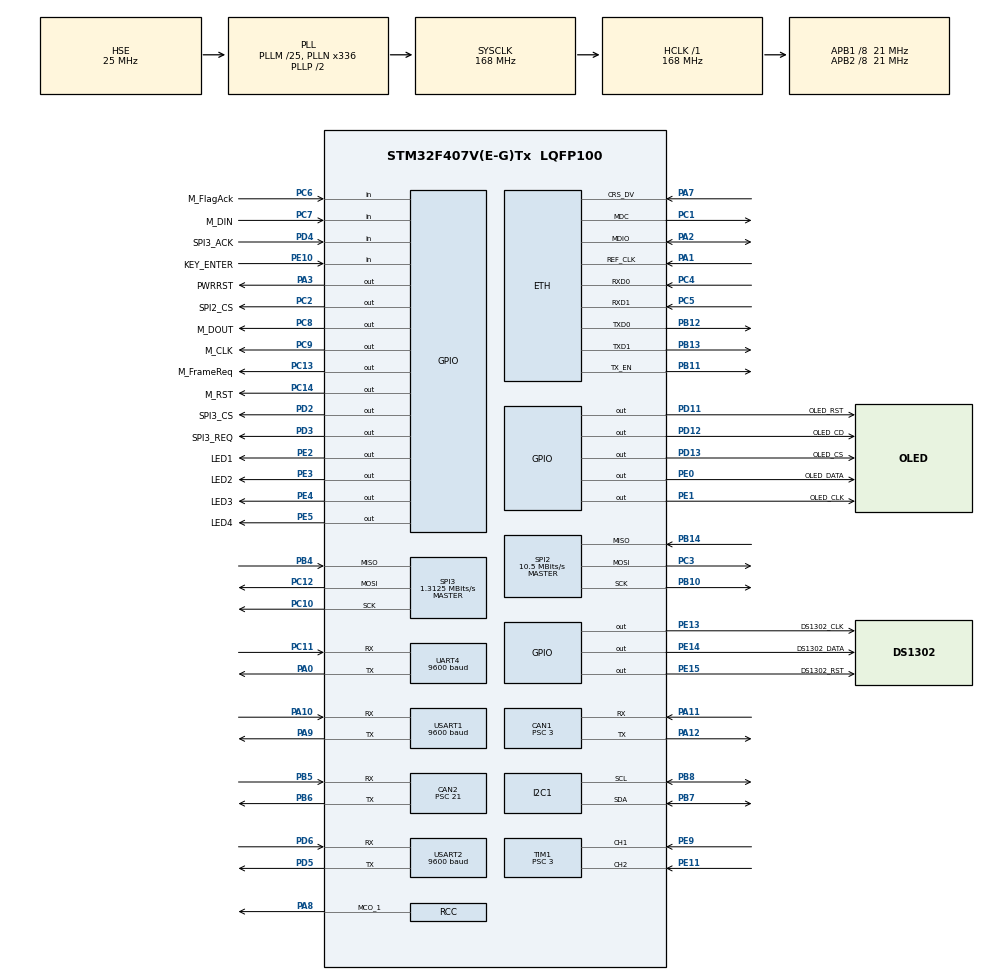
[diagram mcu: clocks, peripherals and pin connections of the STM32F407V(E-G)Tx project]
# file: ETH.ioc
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CAN1.BS1=CAN_BS1_4TQ
CAN1.BS2=CAN_BS2_2TQ
CAN1.CalculateBaudRate=1000000
CAN1.CalculateTimeQuantum=142.85714285714286
CAN1.Mode=CAN_MODE_NORMAL
CAN1.Prescaler=3
CAN2.BS1=CAN_BS1_5TQ
CAN2.BS2=CAN_BS2_2TQ
CAN2.CalculateBaudRate=125000
CAN2.CalculateTimeBit=8000
CAN2.CalculateTimeQuantum=1000.0
CAN2.Mode=CAN_MODE_NORMAL
CAN2.Prescaler=21
Dma.Request0=USART1_RX
Dma.Request1=USART1_TX
Dma.Request2=USART2_RX
Dma.Request3=USART2_TX
Dma.Request4=UART4_RX
Dma.Request5=UART4_TX
Dma.UART4_RX.4.Direction=DMA_PERIPH_TO_MEMORY
Dma.UART4_RX.4.FIFOMode=DMA_FIFOMODE_DISABLE
Dma.UART4_RX.4.Instance=DMA1_Stream2
Dma.UART4_RX.4.MemDataAlignment=DMA_MDATAALIGN_BYTE
Dma.UART4_RX.4.MemInc=DMA_MINC_ENABLE
Dma.UART4_RX.4.Mode=DMA_NORMAL
Dma.UART4_RX.4.PeriphDataAlignment=DMA_PDATAALIGN_BYTE
Dma.UART4_RX.4.PeriphInc=DMA_PINC_DISABLE
Dma.UART4_RX.4.Priority=DMA_PRIORITY_LOW
Dma.UART4_TX.5.Direction=DMA_MEMORY_TO_PERIPH
Dma.UART4_TX.5.FIFOMode=DMA_FIFOMODE_DISABLE
Dma.UART4_TX.5.Instance=DMA1_Stream4
Dma.UART4_TX.5.MemDataAlignment=DMA_MDATAALIGN_BYTE
Dma.UART4_TX.5.MemInc=DMA_MINC_ENABLE
Dma.UART4_TX.5.Mode=DMA_NORMAL
Dma.UART4_TX.5.PeriphDataAlignment=DMA_PDATAALIGN_BYTE
Dma.UART4_TX.5.PeriphInc=DMA_PINC_DISABLE
Dma.UART4_TX.5.Priority=DMA_PRIORITY_LOW
Dma.USART1_RX.0.Direction=DMA_PERIPH_TO_MEMORY
Dma.USART1_RX.0.FIFOMode=DMA_FIFOMODE_DISABLE
Dma.USART1_RX.0.Instance=DMA2_Stream2
Dma.USART1_RX.0.MemDataAlignment=DMA_MDATAALIGN_BYTE
Dma.USART1_RX.0.MemInc=DMA_MINC_ENABLE
Dma.USART1_RX.0.Mode=DMA_NORMAL
Dma.USART1_RX.0.PeriphDataAlignment=DMA_PDATAALIGN_BYTE
Dma.USART1_RX.0.PeriphInc=DMA_PINC_DISABLE
Dma.USART1_RX.0.Priority=DMA_PRIORITY_LOW
Dma.USART1_TX.1.Direction=DMA_MEMORY_TO_PERIPH
Dma.USART1_TX.1.FIFOMode=DMA_FIFOMODE_DISABLE
Dma.USART1_TX.1.Instance=DMA2_Stream7
Dma.USART1_TX.1.MemDataAlignment=DMA_MDATAALIGN_BYTE
Dma.USART1_TX.1.MemInc=DMA_MINC_ENABLE
Dma.USART1_TX.1.Mode=DMA_NORMAL
Dma.USART1_TX.1.PeriphDataAlignment=DMA_PDATAALIGN_BYTE
Dma.USART1_TX.1.PeriphInc=DMA_PINC_DISABLE
Dma.USART1_TX.1.Priority=DMA_PRIORITY_LOW
Dma.USART2_RX.2.Direction=DMA_PERIPH_TO_MEMORY
Dma.USART2_RX.2.FIFOMode=DMA_FIFOMODE_DISABLE
Dma.USART2_RX.2.Instance=DMA1_Stream5
Dma.USART2_RX.2.MemDataAlignment=DMA_MDATAALIGN_BYTE
Dma.USART2_RX.2.MemInc=DMA_MINC_ENABLE
Dma.USART2_RX.2.Mode=DMA_NORMAL
Dma.USART2_RX.2.PeriphDataAlignment=DMA_PDATAALIGN_BYTE
Dma.USART2_RX.2.PeriphInc=DMA_PINC_DISABLE
Dma.USART2_RX.2.Priority=DMA_PRIORITY_LOW
Dma.USART2_TX.3.Direction=DMA_MEMORY_TO_PERIPH
Dma.USART2_TX.3.FIFOMode=DMA_FIFOMODE_DISABLE
Dma.USART2_TX.3.Instance=DMA1_Stream6
Dma.USART2_TX.3.MemDataAlignment=DMA_MDATAALIGN_BYTE
Dma.USART2_TX.3.MemInc=DMA_MINC_ENABLE
Dma.USART2_TX.3.Mode=DMA_NORMAL
Dma.USART2_TX.3.PeriphDataAlignment=DMA_PDATAALIGN_BYTE
Dma.USART2_TX.3.PeriphInc=DMA_PINC_DISABLE
Dma.USART2_TX.3.Priority=DMA_PRIORITY_LOW
ETH.MediaInterface=HAL_ETH_RMII_MODE
ETH.PHY_DUPLEX_STATUS=0x0010
ETH.PHY_Name_RMII=userPHY
ETH.PHY_SPEED_STATUS=0x0004
ETH.PHY_SR=31
ETH.PHY_User_Name=LAN8720
I2C1.OwnAddress=20
Mcu.Family=STM32F4
Mcu.Name=STM32F407V(E-G)Tx
Mcu.Package=LQFP100
NVIC.CAN1_RX0_IRQn=true\:0\:0\:false\:false\:true\:true\:true\:true
NVIC.CAN1_TX_IRQn=true\:0\:0\:false\:false\:true\:true\:true\:true
NVIC.CAN2_RX0_IRQn=true\:0\:0\:false\:false\:true\:true\:true\:true
NVIC.DMA1_Stream2_IRQn=true\:0\:0\:false\:false\:true\:false\:true\:true
NVIC.DMA1_Stream4_IRQn=true\:0\:0\:false\:false\:true\:false\:true\:true
NVIC.DMA1_Stream5_IRQn=true\:0\:0\:false\:false\:true\:false\:true\:true
NVIC.DMA1_Stream6_IRQn=true\:0\:0\:false\:false\:true\:false\:true\:true
NVIC.DMA2_Stream2_IRQn=true\:0\:0\:false\:false\:true\:false\:true\:true
NVIC.DMA2_Stream7_IRQn=true\:0\:0\:false\:false\:true\:false\:true\:true
NVIC.ETH_IRQn=true\:0\:0\:false\:false\:true\:true\:true\:true
NVIC.PriorityGroup=NVIC_PRIORITYGROUP_4
NVIC.TIM6_DAC_IRQn=true\:15\:0\:false\:false\:true\:false\:true\:true
NVIC.TimeBase=TIM6_DAC_IRQn
NVIC.TimeBaseIP=TIM6
NVIC.UART4_IRQn=true\:0\:0\:false\:false\:true\:true\:true\:true
NVIC.USART1_IRQn=true\:0\:0\:false\:false\:true\:true\:true\:true
NVIC.USART2_IRQn=true\:0\:0\:false\:false\:true\:true\:true\:true
PA0-WKUP.Mode=Asynchronous
PA0-WKUP.Signal=UART4_TX
PA1.Mode=RMII
PA1.Signal=ETH_REF_CLK
PA10.Mode=Asynchronous
PA10.Signal=USART1_RX
PA11.Mode=CAN_Activate
PA11.Signal=CAN1_RX
PA12.Mode=CAN_Activate
PA12.Signal=CAN1_TX
PA13.Mode=Serial_Wire
PA13.Signal=SYS_JTMS-SWDIO
PA14.Mode=Serial_Wire
PA14.Signal=SYS_JTCK-SWCLK
PA2.Mode=RMII
PA2.Signal=ETH_MDIO
PA3.GPIO_Label=PWRRST
PA3.Signal=GPIO_Output
PA7.Mode=RMII
PA7.Signal=ETH_CRS_DV
PA8.Mode=Clock-out-1
PA8.Signal=RCC_MCO_1
PA9.Mode=Asynchronous
PA9.Signal=USART1_TX
PB10.Mode=Full_Duplex_Master
PB10.Signal=SPI2_SCK
PB11.Mode=RMII
PB11.Signal=ETH_TX_EN
PB12.Mode=RMII
PB12.Signal=ETH_TXD0
PB13.Mode=RMII
PB13.Signal=ETH_TXD1
PB14.Mode=Full_Duplex_Master
PB14.Signal=SPI2_MISO
PB4.Mode=Full_Duplex_Master
PB4.Signal=SPI3_MISO
PB5.Mode=CAN_Activate
PB5.Signal=CAN2_RX
PB6.Mode=CAN_Activate
PB6.Signal=CAN2_TX
PB7.GPIO_Pu=GPIO_PULLUP
PB7.Mode=I2C
PB7.Signal=I2C1_SDA
PB8.GPIO_Pu=GPIO_PULLUP
PB8.Mode=I2C
PB8.Signal=I2C1_SCL
PC1.Mode=RMII
PC1.Signal=ETH_MDC
PC10.Mode=Full_Duplex_Master
PC10.Signal=SPI3_SCK
PC11.Mode=Asynchronous
PC11.Signal=UART4_RX
PC12.Mode=Full_Duplex_Master
PC12.Signal=SPI3_MOSI
PC13-ANTI_TAMP.GPIO_Label=M_FrameReq
PC13-ANTI_TAMP.Signal=GPIO_Output
PC14-OSC32_IN.GPIO_Label=M_RST
PC14-OSC32_IN.Signal=GPIO_Output
PC2.GPIO_Label=SPI2_CS
PC2.Signal=GPIO_Output
PC3.Mode=Full_Duplex_Master
PC3.Signal=SPI2_MOSI
PC4.Mode=RMII
PC4.Signal=ETH_RXD0
PC5.Mode=RMII
PC5.Signal=ETH_RXD1
PC6.GPIO_Label=M_FlagAck
PC6.Signal=GPIO_Input
PC7.GPIO_Label=M_DIN
PC7.Signal=GPIO_Input
PC8.GPIO_Label=M_DOUT
PC8.Signal=GPIO_Output
PC9.GPIO_Label=M_CLK
PC9.Signal=GPIO_Output
PD11.GPIO_Label=OLED_RST
PD11.Signal=GPIO_Output
PD12.GPIO_Label=OLED_CD
PD12.Signal=GPIO_Output
PD13.GPIO_Label=OLED_CS
PD13.Signal=GPIO_Output
PD2.GPIO_Label=SPI3_CS
PD2.Signal=GPIO_Output
PD3.GPIO_Label=SPI3_REQ
PD3.Signal=GPIO_Output
PD4.GPIO_Label=SPI3_ACK
PD4.Signal=GPIO_Input
PD5.Mode=Asynchronous
PD5.Signal=USART2_TX
PD6.Mode=Asynchronous
PD6.Signal=USART2_RX
PE0.GPIO_Label=OLED_DATA
PE0.Signal=GPIO_Output
PE1.GPIO_Label=OLED_CLK
PE1.Signal=GPIO_Output
PE10.GPIO_Label=KEY_ENTER
PE10.Signal=GPIO_Input
PE11.Signal=S_TIM1_CH2
PE13.GPIO_Label=DS1302_CLK
PE13.Signal=GPIO_Output
PE14.GPIO_Label=DS1302_DATA
PE14.Signal=GPIO_Output
PE15.GPIO_Label=DS1302_RST
PE15.Signal=GPIO_Output
PE2.GPIO_Label=LED1
PE2.Signal=GPIO_Output
PE3.GPIO_Label=LED2
PE3.Signal=GPIO_Output
PE4.GPIO_Label=LED3
PE4.Signal=GPIO_Output
PE5.GPIO_Label=LED4
PE5.Signal=GPIO_Output
PE9.Signal=S_TIM1_CH1
PH0-OSC_IN.Mode=HSE-External-Oscillator
PH0-OSC_IN.Signal=RCC_OSC_IN
PH1-OSC_OUT.Mode=HSE-External-Oscillator
PH1-OSC_OUT.Signal=RCC_OSC_OUT
ProjectManager.HeapSize=0x200
ProjectManager.StackSize=0x400
ProjectManager.TargetToolchain=Makefile
RCC.48MHZClocksFreq_Value=84000000
RCC.AHBFreq_Value=168000000
RCC.APB1CLKDivider=RCC_HCLK_DIV8
RCC.APB1Freq_Value=21000000
RCC.APB1TimFreq_Value=42000000
RCC.APB2CLKDivider=RCC_HCLK_DIV8
RCC.APB2Freq_Value=21000000
RCC.APB2TimFreq_Value=42000000
RCC.CortexFreq_Value=168000000
RCC.HCLKFreq_Value=168000000
RCC.HSE_VALUE=25000000
RCC.HSI_VALUE=16000000
RCC.LSE_VALUE=32768
RCC.PLLM=25
RCC.PLLN=336
RCC.PLLSourceVirtual=RCC_PLLSOURCE_HSE
RCC.RCC_RTC_Clock_Source=RCC_RTCCLKSOURCE_HSE_DIV25
RCC.RCC_RTC_Clock_SourceVirtual=RCC_RTCCLKSOURCE_LSE
RCC.RCC_RTC_Clock_Source_FROM_HSE=RCC_RTCCLKSOURCE_HSE_DIV25
RCC.SYSCLKFreq_VALUE=168000000
RCC.SYSCLKSource=RCC_SYSCLKSOURCE_PLLCLK
RCC.VCOOutputFreq_Value=336000000
SH.S_TIM1_CH1.0=TIM1_CH1,Encoder_Interface
SH.S_TIM1_CH2.0=TIM1_CH2,Encoder_Interface
SPI2.CalculateBaudRate=10.5 MBits/s
SPI2.Direction=SPI_DIRECTION_2LINES
SPI2.Mode=SPI_MODE_MASTER
SPI2.VirtualType=VM_MASTER
SPI3.BaudRatePrescaler=SPI_BAUDRATEPRESCALER_16
SPI3.CLKPhase=SPI_PHASE_1EDGE
SPI3.CLKPolarity=SPI_POLARITY_LOW
SPI3.CalculateBaudRate=1.3125 MBits/s
SPI3.Direction=SPI_DIRECTION_2LINES
SPI3.FirstBit=SPI_FIRSTBIT_MSB
SPI3.Mode=SPI_MODE_MASTER
SPI3.VirtualType=VM_MASTER
TIM1.Channel-Input_Capture2_from_TI2=TIM_CHANNEL_2
TIM1.EncoderMode=TIM_ENCODERMODE_TI12
TIM1.IC1Filter=15
TIM1.IC2Filter=15
TIM1.Period=0xffff
TIM1.Prescaler=3
UART4.BaudRate=9600
UART4.VirtualMode=Asynchronous
USART1.BaudRate=9600
USART1.VirtualMode=VM_ASYNC
USART2.BaudRate=9600
USART2.VirtualMode=VM_ASYNC
VP_SYS_VS_tim6.Mode=TIM6
board=custom

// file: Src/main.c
/* USER CODE BEGIN Header */
/**
  ******************************************************************************
  * @file           : main.c
  * @brief          : Main program body
  ******************************************************************************
  * @attention
  *
  * Copyright (c) 2023 STMicroelectronics.
  * All rights reserved.
  *
  * This software is licensed under terms that can be found in the LICENSE file
  * in the root directory of this software component.
  * If no LICENSE file comes with this software, it is provided AS-IS.
  *
  ******************************************************************************
  */
/* USER CODE END Header */
#include "main.h"
#include "string.h"

/* USER CODE BEGIN Includes */
#include "mongoose.h"
/* USER CODE END Includes */

ETH_TxPacketConfig TxConfig;
ETH_DMADescTypeDef  DMARxDscrTab[ETH_RX_DESC_CNT]; /* Ethernet Rx DMA Descriptors */
ETH_DMADescTypeDef  DMATxDscrTab[ETH_TX_DESC_CNT]; /* Ethernet Tx DMA Descriptors */

CAN_HandleTypeDef hcan1;
CAN_HandleTypeDef hcan2;

ETH_HandleTypeDef heth;

I2C_HandleTypeDef hi2c1;

SPI_HandleTypeDef hspi2;
SPI_HandleTypeDef hspi3;

TIM_HandleTypeDef htim1;

UART_HandleTypeDef huart4;
UART_HandleTypeDef huart1;
UART_HandleTypeDef huart2;
DMA_HandleTypeDef hdma_uart4_rx;
DMA_HandleTypeDef hdma_uart4_tx;
DMA_HandleTypeDef hdma_usart1_rx;
DMA_HandleTypeDef hdma_usart1_tx;
DMA_HandleTypeDef hdma_usart2_rx;
DMA_HandleTypeDef hdma_usart2_tx;

void SystemClock_Config(void);
static void MX_GPIO_Init(void);
static void MX_DMA_Init(void);
static void MX_USART1_UART_Init(void);
static void MX_SPI3_Init(void);
static void MX_USART2_UART_Init(void);
static void MX_CAN1_Init(void);
static void MX_I2C1_Init(void);
static void MX_UART4_Init(void);
static void MX_SPI2_Init(void);
static void MX_CAN2_Init(void);
static void MX_TIM1_Init(void);
static void MX_ETH_Init(void);

/* USER CODE BEGIN 0 */
uint64_t mg_millis(void) {
  return HAL_GetTick();
}

/* USER CODE END 0 */

int main(void)
{

  /* MCU Configuration--------------------------------------------------------*/

  /* Reset of all peripherals, Initializes the Flash interface and the Systick. */
  HAL_Init();

  /* Configure the system clock */
  SystemClock_Config();

  /* Initialize all configured peripherals */
  MX_GPIO_Init();
  MX_DMA_Init();
  MX_USART1_UART_Init();
  MX_SPI3_Init();
  MX_USART2_UART_Init();
  MX_CAN1_Init();
  MX_I2C1_Init();
  MX_UART4_Init();
  MX_SPI2_Init();
  MX_CAN2_Init();
  MX_TIM1_Init();
  MX_ETH_Init();
  /* USER CODE BEGIN 2 */
  struct mg_mgr mgr;
mg_mgr_init(&mgr);

struct mg_tcpip_if mif = {
    .mac = {2, 0, 1, 2, 3, 4},
    .driver = &mg_tcpip_driver_stm32,
};
mg_tcpip_init(&mgr, &mif);

extern void device_dashboard_fn(struct mg_connection *c, int ev, void *ev_data,
                                void *fn_data);
mg_http_listen(&mgr, "http://0.0.0.0", device_dashboard_fn, NULL);
for (;;) mg_mgr_poll(&mgr, 100);
  /* USER CODE END 2 */

  /* Infinite loop */
  while (1)
  {

  }
}

void SystemClock_Config(void)
{
  RCC_OscInitTypeDef RCC_OscInitStruct = {0};
  RCC_ClkInitTypeDef RCC_ClkInitStruct = {0};

  /** Configure the main internal regulator output voltage
  */
  __HAL_RCC_PWR_CLK_ENABLE();
  __HAL_PWR_VOLTAGESCALING_CONFIG(PWR_REGULATOR_VOLTAGE_SCALE1);

  /** Initializes the RCC Oscillators according to the specified parameters
  * in the RCC_OscInitTypeDef structure.
  */
  RCC_OscInitStruct.OscillatorType = RCC_OSCILLATORTYPE_HSI|RCC_OSCILLATORTYPE_HSE;
  RCC_OscInitStruct.HSEState = RCC_HSE_ON;
  RCC_OscInitStruct.HSIState = RCC_HSI_ON;
  RCC_OscInitStruct.HSICalibrationValue = RCC_HSICALIBRATION_DEFAULT;
  RCC_OscInitStruct.PLL.PLLState = RCC_PLL_ON;
  RCC_OscInitStruct.PLL.PLLSource = RCC_PLLSOURCE_HSE;
  RCC_OscInitStruct.PLL.PLLM = 25;
  RCC_OscInitStruct.PLL.PLLN = 336;
  RCC_OscInitStruct.PLL.PLLP = RCC_PLLP_DIV2;
  RCC_OscInitStruct.PLL.PLLQ = 4;
  if (HAL_RCC_OscConfig(&RCC_OscInitStruct) != HAL_OK)
  {
    Error_Handler();
  }

  /** Initializes the CPU, AHB and APB buses clocks
  */
  RCC_ClkInitStruct.ClockType = RCC_CLOCKTYPE_HCLK|RCC_CLOCKTYPE_SYSCLK
                              |RCC_CLOCKTYPE_PCLK1|RCC_CLOCKTYPE_PCLK2;
  RCC_ClkInitStruct.SYSCLKSource = RCC_SYSCLKSOURCE_PLLCLK;
  RCC_ClkInitStruct.AHBCLKDivider = RCC_SYSCLK_DIV1;
  RCC_ClkInitStruct.APB1CLKDivider = RCC_HCLK_DIV8;
  RCC_ClkInitStruct.APB2CLKDivider = RCC_HCLK_DIV8;

  if (HAL_RCC_ClockConfig(&RCC_ClkInitStruct, FLASH_LATENCY_5) != HAL_OK)
  {
    Error_Handler();
  }
  HAL_RCC_MCOConfig(RCC_MCO1, RCC_MCO1SOURCE_HSI, RCC_MCODIV_1);
}

static void MX_CAN1_Init(void)
{

  hcan1.Instance = CAN1;
  hcan1.Init.Prescaler = 3;
  hcan1.Init.Mode = CAN_MODE_NORMAL;
  hcan1.Init.SyncJumpWidth = CAN_SJW_1TQ;
  hcan1.Init.TimeSeg1 = CAN_BS1_4TQ;
  hcan1.Init.TimeSeg2 = CAN_BS2_2TQ;
  hcan1.Init.TimeTriggeredMode = DISABLE;
  hcan1.Init.AutoBusOff = DISABLE;
  hcan1.Init.AutoWakeUp = DISABLE;
  hcan1.Init.AutoRetransmission = DISABLE;
  hcan1.Init.ReceiveFifoLocked = DISABLE;
  hcan1.Init.TransmitFifoPriority = DISABLE;
  if (HAL_CAN_Init(&hcan1) != HAL_OK)
  {
    Error_Handler();
  }

}

static void MX_CAN2_Init(void)
{

  hcan2.Instance = CAN2;
  hcan2.Init.Prescaler = 21;
  hcan2.Init.Mode = CAN_MODE_NORMAL;
  hcan2.Init.SyncJumpWidth = CAN_SJW_1TQ;
  hcan2.Init.TimeSeg1 = CAN_BS1_5TQ;
  hcan2.Init.TimeSeg2 = CAN_BS2_2TQ;
  hcan2.Init.TimeTriggeredMode = DISABLE;
  hcan2.Init.AutoBusOff = DISABLE;
  hcan2.Init.AutoWakeUp = DISABLE;
  hcan2.Init.AutoRetransmission = DISABLE;
  hcan2.Init.ReceiveFifoLocked = DISABLE;
  hcan2.Init.TransmitFifoPriority = DISABLE;
  if (HAL_CAN_Init(&hcan2) != HAL_OK)
  {
    Error_Handler();
  }

}

static void MX_ETH_Init(void)
{

   static uint8_t MACAddr[6];

  heth.Instance = ETH;
  MACAddr[0] = 0x00;
  MACAddr[1] = 0x80;
  MACAddr[2] = 0xE1;
  MACAddr[3] = 0x00;
  MACAddr[4] = 0x00;
  MACAddr[5] = 0x00;
  heth.Init.MACAddr = &MACAddr[0];
  heth.Init.MediaInterface = HAL_ETH_RMII_MODE;
  heth.Init.TxDesc = DMATxDscrTab;
  heth.Init.RxDesc = DMARxDscrTab;
  heth.Init.RxBuffLen = 1524;

  if (HAL_ETH_Init(&heth) != HAL_OK)
  {
    Error_Handler();
  }

  memset(&TxConfig, 0 , sizeof(ETH_TxPacketConfig));
  TxConfig.Attributes = ETH_TX_PACKETS_FEATURES_CSUM | ETH_TX_PACKETS_FEATURES_CRCPAD;
  TxConfig.ChecksumCtrl = ETH_CHECKSUM_IPHDR_PAYLOAD_INSERT_PHDR_CALC;
  TxConfig.CRCPadCtrl = ETH_CRC_PAD_INSERT;

}

static void MX_I2C1_Init(void)
{

  hi2c1.Instance = I2C1;
  hi2c1.Init.ClockSpeed = 100000;
  hi2c1.Init.DutyCycle = I2C_DUTYCYCLE_2;
  hi2c1.Init.OwnAddress1 = 40;
  hi2c1.Init.AddressingMode = I2C_ADDRESSINGMODE_7BIT;
  hi2c1.Init.DualAddressMode = I2C_DUALADDRESS_DISABLE;
  hi2c1.Init.OwnAddress2 = 0;
  hi2c1.Init.GeneralCallMode = I2C_GENERALCALL_DISABLE;
  hi2c1.Init.NoStretchMode = I2C_NOSTRETCH_DISABLE;
  if (HAL_I2C_Init(&hi2c1) != HAL_OK)
  {
    Error_Handler();
  }

}

static void MX_SPI2_Init(void)
{

  /* SPI2 parameter configuration*/
  hspi2.Instance = SPI2;
  hspi2.Init.Mode = SPI_MODE_MASTER;
  hspi2.Init.Direction = SPI_DIRECTION_2LINES;
  hspi2.Init.DataSize = SPI_DATASIZE_8BIT;
  hspi2.Init.CLKPolarity = SPI_POLARITY_LOW;
  hspi2.Init.CLKPhase = SPI_PHASE_1EDGE;
  hspi2.Init.NSS = SPI_NSS_SOFT;
  hspi2.Init.BaudRatePrescaler = SPI_BAUDRATEPRESCALER_2;
  hspi2.Init.FirstBit = SPI_FIRSTBIT_MSB;
  hspi2.Init.TIMode = SPI_TIMODE_DISABLE;
  hspi2.Init.CRCCalculation = SPI_CRCCALCULATION_DISABLE;
  hspi2.Init.CRCPolynomial = 10;
  if (HAL_SPI_Init(&hspi2) != HAL_OK)
  {
    Error_Handler();
  }

}

static void MX_SPI3_Init(void)
{

  /* SPI3 parameter configuration*/
  hspi3.Instance = SPI3;
  hspi3.Init.Mode = SPI_MODE_MASTER;
  hspi3.Init.Direction = SPI_DIRECTION_2LINES;
  hspi3.Init.DataSize = SPI_DATASIZE_8BIT;
  hspi3.Init.CLKPolarity = SPI_POLARITY_LOW;
  hspi3.Init.CLKPhase = SPI_PHASE_1EDGE;
  hspi3.Init.NSS = SPI_NSS_SOFT;
  hspi3.Init.BaudRatePrescaler = SPI_BAUDRATEPRESCALER_16;
  hspi3.Init.FirstBit = SPI_FIRSTBIT_MSB;
  hspi3.Init.TIMode = SPI_TIMODE_DISABLE;
  hspi3.Init.CRCCalculation = SPI_CRCCALCULATION_DISABLE;
  hspi3.Init.CRCPolynomial = 10;
  if (HAL_SPI_Init(&hspi3) != HAL_OK)
  {
    Error_Handler();
  }

}

static void MX_TIM1_Init(void)
{

  TIM_Encoder_InitTypeDef sConfig = {0};
  TIM_MasterConfigTypeDef sMasterConfig = {0};

  htim1.Instance = TIM1;
  htim1.Init.Prescaler = 3;
  htim1.Init.CounterMode = TIM_COUNTERMODE_UP;
  htim1.Init.Period = 0xffff;
  htim1.Init.ClockDivision = TIM_CLOCKDIVISION_DIV1;
  htim1.Init.RepetitionCounter = 0;
  htim1.Init.AutoReloadPreload = TIM_AUTORELOAD_PRELOAD_DISABLE;
  sConfig.EncoderMode = TIM_ENCODERMODE_TI12;
  sConfig.IC1Polarity = TIM_ICPOLARITY_RISING;
  sConfig.IC1Selection = TIM_ICSELECTION_DIRECTTI;
  sConfig.IC1Prescaler = TIM_ICPSC_DIV1;
  sConfig.IC1Filter = 15;
  sConfig.IC2Polarity = TIM_ICPOLARITY_RISING;
  sConfig.IC2Selection = TIM_ICSELECTION_DIRECTTI;
  sConfig.IC2Prescaler = TIM_ICPSC_DIV1;
  sConfig.IC2Filter = 15;
  if (HAL_TIM_Encoder_Init(&htim1, &sConfig) != HAL_OK)
  {
    Error_Handler();
  }
  sMasterConfig.MasterOutputTrigger = TIM_TRGO_RESET;
  sMasterConfig.MasterSlaveMode = TIM_MASTERSLAVEMODE_DISABLE;
  if (HAL_TIMEx_MasterConfigSynchronization(&htim1, &sMasterConfig) != HAL_OK)
  {
    Error_Handler();
  }

}

static void MX_UART4_Init(void)
{

  huart4.Instance = UART4;
  huart4.Init.BaudRate = 9600;
  huart4.Init.WordLength = UART_WORDLENGTH_8B;
  huart4.Init.StopBits = UART_STOPBITS_1;
  huart4.Init.Parity = UART_PARITY_NONE;
  huart4.Init.Mode = UART_MODE_TX_RX;
  huart4.Init.HwFlowCtl = UART_HWCONTROL_NONE;
  huart4.Init.OverSampling = UART_OVERSAMPLING_16;
  if (HAL_UART_Init(&huart4) != HAL_OK)
  {
    Error_Handler();
  }

}

static void MX_USART1_UART_Init(void)
{

  huart1.Instance = USART1;
  huart1.Init.BaudRate = 9600;
  huart1.Init.WordLength = UART_WORDLENGTH_8B;
  huart1.Init.StopBits = UART_STOPBITS_1;
  huart1.Init.Parity = UART_PARITY_NONE;
  huart1.Init.Mode = UART_MODE_TX_RX;
  huart1.Init.HwFlowCtl = UART_HWCONTROL_NONE;
  huart1.Init.OverSampling = UART_OVERSAMPLING_16;
  if (HAL_UART_Init(&huart1) != HAL_OK)
  {
    Error_Handler();
  }

}

static void MX_USART2_UART_Init(void)
{

  huart2.Instance = USART2;
  huart2.Init.BaudRate = 9600;
  huart2.Init.WordLength = UART_WORDLENGTH_8B;
  huart2.Init.StopBits = UART_STOPBITS_1;
  huart2.Init.Parity = UART_PARITY_NONE;
  huart2.Init.Mode = UART_MODE_TX_RX;
  huart2.Init.HwFlowCtl = UART_HWCONTROL_NONE;
  huart2.Init.OverSampling = UART_OVERSAMPLING_16;
  if (HAL_UART_Init(&huart2) != HAL_OK)
  {
    Error_Handler();
  }

}

static void MX_DMA_Init(void)
{

  /* DMA controller clock enable */
  __HAL_RCC_DMA2_CLK_ENABLE();
  __HAL_RCC_DMA1_CLK_ENABLE();

  /* DMA interrupt init */
  /* DMA1_Stream2_IRQn interrupt configuration */
  HAL_NVIC_SetPriority(DMA1_Stream2_IRQn, 0, 0);
  HAL_NVIC_EnableIRQ(DMA1_Stream2_IRQn);
  /* DMA1_Stream4_IRQn interrupt configuration */
  HAL_NVIC_SetPriority(DMA1_Stream4_IRQn, 0, 0);
  HAL_NVIC_EnableIRQ(DMA1_Stream4_IRQn);
  /* DMA1_Stream5_IRQn interrupt configuration */
  HAL_NVIC_SetPriority(DMA1_Stream5_IRQn, 0, 0);
  HAL_NVIC_EnableIRQ(DMA1_Stream5_IRQn);
  /* DMA1_Stream6_IRQn interrupt configuration */
  HAL_NVIC_SetPriority(DMA1_Stream6_IRQn, 0, 0);
  HAL_NVIC_EnableIRQ(DMA1_Stream6_IRQn);
  /* DMA2_Stream2_IRQn interrupt configuration */
  HAL_NVIC_SetPriority(DMA2_Stream2_IRQn, 0, 0);
  HAL_NVIC_EnableIRQ(DMA2_Stream2_IRQn);
  /* DMA2_Stream7_IRQn interrupt configuration */
  HAL_NVIC_SetPriority(DMA2_Stream7_IRQn, 0, 0);
  HAL_NVIC_EnableIRQ(DMA2_Stream7_IRQn);

}

static void MX_GPIO_Init(void)
{
  GPIO_InitTypeDef GPIO_InitStruct = {0};

  /* GPIO Ports Clock Enable */
  __HAL_RCC_GPIOE_CLK_ENABLE();
  __HAL_RCC_GPIOC_CLK_ENABLE();
  __HAL_RCC_GPIOH_CLK_ENABLE();
  __HAL_RCC_GPIOA_CLK_ENABLE();
  __HAL_RCC_GPIOB_CLK_ENABLE();
  __HAL_RCC_GPIOD_CLK_ENABLE();

  /*Configure GPIO pin Output Level */
  HAL_GPIO_WritePin(GPIOE, LED1_Pin|LED2_Pin|LED3_Pin|LED4_Pin
                          |DS1302_CLK_Pin|DS1302_DATA_Pin|DS1302_RST_Pin|OLED_DATA_Pin
                          |OLED_CLK_Pin, GPIO_PIN_RESET);

  /*Configure GPIO pin Output Level */
  HAL_GPIO_WritePin(GPIOC, M_FrameReq_Pin|M_RST_Pin|SPI2_CS_Pin|M_DOUT_Pin
                          |M_CLK_Pin, GPIO_PIN_RESET);

  /*Configure GPIO pin Output Level */
  HAL_GPIO_WritePin(PWRRST_GPIO_Port, PWRRST_Pin, GPIO_PIN_RESET);

  /*Configure GPIO pin Output Level */
  HAL_GPIO_WritePin(GPIOD, OLED_RST_Pin|OLED_CD_Pin|OLED_CS_Pin|SPI3_CS_Pin
                          |SPI3_REQ_Pin, GPIO_PIN_RESET);

  /*Configure GPIO pins : LED1_Pin LED2_Pin LED3_Pin LED4_Pin
                           DS1302_CLK_Pin DS1302_DATA_Pin DS1302_RST_Pin OLED_DATA_Pin
                           OLED_CLK_Pin */
  GPIO_InitStruct.Pin = LED1_Pin|LED2_Pin|LED3_Pin|LED4_Pin
                          |DS1302_CLK_Pin|DS1302_DATA_Pin|DS1302_RST_Pin|OLED_DATA_Pin
                          |OLED_CLK_Pin;
  GPIO_InitStruct.Mode = GPIO_MODE_OUTPUT_PP;
  GPIO_InitStruct.Pull = GPIO_NOPULL;
  GPIO_InitStruct.Speed = GPIO_SPEED_FREQ_LOW;
  HAL_GPIO_Init(GPIOE, &GPIO_InitStruct);

  /*Configure GPIO pins : M_FrameReq_Pin M_RST_Pin SPI2_CS_Pin M_DOUT_Pin
                           M_CLK_Pin */
  GPIO_InitStruct.Pin = M_FrameReq_Pin|M_RST_Pin|SPI2_CS_Pin|M_DOUT_Pin
                          |M_CLK_Pin;
  GPIO_InitStruct.Mode = GPIO_MODE_OUTPUT_PP;
  GPIO_InitStruct.Pull = GPIO_NOPULL;
  GPIO_InitStruct.Speed = GPIO_SPEED_FREQ_LOW;
  HAL_GPIO_Init(GPIOC, &GPIO_InitStruct);

  /*Configure GPIO pin : PWRRST_Pin */
  GPIO_InitStruct.Pin = PWRRST_Pin;
  GPIO_InitStruct.Mode = GPIO_MODE_OUTPUT_PP;
  GPIO_InitStruct.Pull = GPIO_NOPULL;
  GPIO_InitStruct.Speed = GPIO_SPEED_FREQ_LOW;
  HAL_GPIO_Init(PWRRST_GPIO_Port, &GPIO_InitStruct);

  /*Configure GPIO pin : KEY_ENTER_Pin */
  GPIO_InitStruct.Pin = KEY_ENTER_Pin;
  GPIO_InitStruct.Mode = GPIO_MODE_INPUT;
  GPIO_InitStruct.Pull = GPIO_NOPULL;
  HAL_GPIO_Init(KEY_ENTER_GPIO_Port, &GPIO_InitStruct);

  /*Configure GPIO pins : OLED_RST_Pin OLED_CD_Pin OLED_CS_Pin SPI3_CS_Pin
                           SPI3_REQ_Pin */
  GPIO_InitStruct.Pin = OLED_RST_Pin|OLED_CD_Pin|OLED_CS_Pin|SPI3_CS_Pin
                          |SPI3_REQ_Pin;
  GPIO_InitStruct.Mode = GPIO_MODE_OUTPUT_PP;
  GPIO_InitStruct.Pull = GPIO_NOPULL;
  GPIO_InitStruct.Speed = GPIO_SPEED_FREQ_LOW;
  HAL_GPIO_Init(GPIOD, &GPIO_InitStruct);

  /*Configure GPIO pins : M_FlagAck_Pin M_DIN_Pin */
  GPIO_InitStruct.Pin = M_FlagAck_Pin|M_DIN_Pin;
  GPIO_InitStruct.Mode = GPIO_MODE_INPUT;
  GPIO_InitStruct.Pull = GPIO_NOPULL;
  HAL_GPIO_Init(GPIOC, &GPIO_InitStruct);

  /*Configure GPIO pin : PA8 */
  GPIO_InitStruct.Pin = GPIO_PIN_8;
  GPIO_InitStruct.Mode = GPIO_MODE_AF_PP;
  GPIO_InitStruct.Pull = GPIO_NOPULL;
  GPIO_InitStruct.Speed = GPIO_SPEED_FREQ_LOW;
  GPIO_InitStruct.Alternate = GPIO_AF0_MCO;
  HAL_GPIO_Init(GPIOA, &GPIO_InitStruct);

  /*Configure GPIO pin : SPI3_ACK_Pin */
  GPIO_InitStruct.Pin = SPI3_ACK_Pin;
  GPIO_InitStruct.Mode = GPIO_MODE_INPUT;
  GPIO_InitStruct.Pull = GPIO_NOPULL;
  HAL_GPIO_Init(SPI3_ACK_GPIO_Port, &GPIO_InitStruct);

}

void HAL_TIM_PeriodElapsedCallback(TIM_HandleTypeDef *htim)
{
  if (htim->Instance == TIM6) {
    HAL_IncTick();
  }
}

void Error_Handler(void)
{
  __disable_irq();
  while (1)
  {
  }
}
